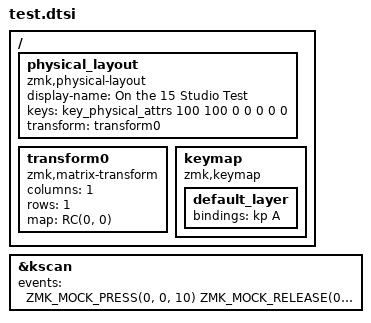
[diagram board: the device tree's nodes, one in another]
#include <physical_layouts.dtsi>
#include <dt-bindings/zmk/matrix_transform.h>

/ {
    physical_layout: physical_layout {
        compatible = "zmk,physical-layout";
        display-name = "On the 15 Studio Test";
        keys = <&key_physical_attrs 100 100 0 0 0 0 0>;
        transform = <&transform0>;
    };

    transform0: transform0 {
        compatible = "zmk,matrix-transform";
        columns = <1>;
        rows = <1>;
        map = <RC(0, 0)>;
    };
};

#include <dt-bindings/zmk/keys.h>
#include <dt-bindings/zmk/kscan_mock.h>
#include <behaviors.dtsi>

/ {
    keymap {
        compatible = "zmk,keymap";

        default_layer {
            bindings = <&kp A>;
        };
    };
};

&kscan {
    events = <
        ZMK_MOCK_PRESS(0, 0, 10)
        ZMK_MOCK_RELEASE(0, 0, 10)
    >;
};
